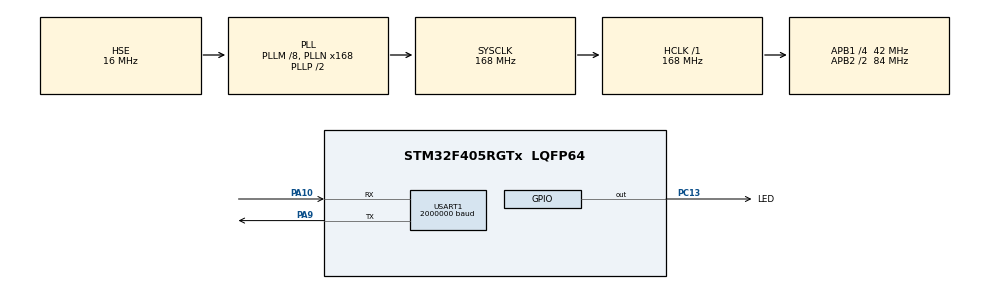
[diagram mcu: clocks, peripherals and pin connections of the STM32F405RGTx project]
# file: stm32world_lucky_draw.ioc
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Dma.Request0=USART1_RX
Dma.USART1_RX.0.Direction=DMA_PERIPH_TO_MEMORY
Dma.USART1_RX.0.FIFOMode=DMA_FIFOMODE_DISABLE
Dma.USART1_RX.0.Instance=DMA2_Stream2
Dma.USART1_RX.0.MemDataAlignment=DMA_MDATAALIGN_BYTE
Dma.USART1_RX.0.MemInc=DMA_MINC_ENABLE
Dma.USART1_RX.0.Mode=DMA_CIRCULAR
Dma.USART1_RX.0.PeriphDataAlignment=DMA_PDATAALIGN_BYTE
Dma.USART1_RX.0.PeriphInc=DMA_PINC_DISABLE
Dma.USART1_RX.0.Priority=DMA_PRIORITY_LOW
Mcu.Family=STM32F4
Mcu.Name=STM32F405RGTx
Mcu.Package=LQFP64
NVIC.DMA2_Stream2_IRQn=true\:0\:0\:false\:false\:true\:false\:true\:true
NVIC.PriorityGroup=NVIC_PRIORITYGROUP_4
NVIC.USART1_IRQn=true\:0\:0\:false\:false\:true\:true\:true\:true
PA10.Mode=Asynchronous
PA10.Signal=USART1_RX
PA13.Mode=Trace_Asynchronous_SW
PA13.Signal=SYS_JTMS-SWDIO
PA14.Mode=Trace_Asynchronous_SW
PA14.Signal=SYS_JTCK-SWCLK
PA9.Mode=Asynchronous
PA9.Signal=USART1_TX
PB3.Mode=Trace_Asynchronous_SW
PB3.Signal=SYS_JTDO-SWO
PC13-ANTI_TAMP.GPIO_Label=LED
PC13-ANTI_TAMP.GPIO_ModeDefaultOutputPP=GPIO_MODE_OUTPUT_PP
PC13-ANTI_TAMP.GPIO_PuPd=GPIO_NOPULL
PC13-ANTI_TAMP.PinState=GPIO_PIN_SET
PC13-ANTI_TAMP.Signal=GPIO_Output
PH0-OSC_IN.Mode=HSE-External-Oscillator
PH0-OSC_IN.Signal=RCC_OSC_IN
PH1-OSC_OUT.Mode=HSE-External-Oscillator
PH1-OSC_OUT.Signal=RCC_OSC_OUT
ProjectManager.HeapSize=0x200
ProjectManager.StackSize=0x400
ProjectManager.TargetToolchain=STM32CubeIDE
RCC.48MHZClocksFreq_Value=48000000
RCC.AHBFreq_Value=168000000
RCC.APB1CLKDivider=RCC_HCLK_DIV4
RCC.APB1Freq_Value=42000000
RCC.APB1TimFreq_Value=84000000
RCC.APB2CLKDivider=RCC_HCLK_DIV2
RCC.APB2Freq_Value=84000000
RCC.APB2TimFreq_Value=168000000
RCC.CortexFreq_Value=168000000
RCC.HCLKFreq_Value=168000000
RCC.HSE_VALUE=16000000
RCC.HSI_VALUE=16000000
RCC.LSE_VALUE=32768
RCC.PLLM=8
RCC.PLLN=168
RCC.PLLQ=7
RCC.PLLSourceVirtual=RCC_PLLSOURCE_HSE
RCC.SYSCLKFreq_VALUE=168000000
RCC.SYSCLKSource=RCC_SYSCLKSOURCE_PLLCLK
RCC.VCOOutputFreq_Value=336000000
USART1.BaudRate=2000000
USART1.OverSampling=UART_OVERSAMPLING_8
USART1.VirtualMode=VM_ASYNC
VP_RNG_VS_RNG.Mode=RNG_Activate
board=custom

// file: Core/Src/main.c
/* USER CODE BEGIN Header */
/**
 ******************************************************************************
 * @file           : main.c
 * @brief          : Main program body
 ******************************************************************************
 * @attention
 *
 * Copyright (c) 2024 Lars Boegild Thomsen <lth@stm32world.com>
 * All rights reserved.
 *
 * This software is licensed under terms that can be found in the LICENSE file
 * in the root directory of this software component.
 * If no LICENSE file comes with this software, it is provided AS-IS.
 *
 ******************************************************************************
 */
/* USER CODE END Header */
#include "main.h"

/* USER CODE BEGIN Includes */
#include <stdlib.h>
#include <stdio.h>
/* USER CODE END Includes */

/* USER CODE BEGIN PD */
#define PARTICIPANTS 3
#define WINNERS 3
/* USER CODE END PD */

RNG_HandleTypeDef hrng;

UART_HandleTypeDef huart1;
DMA_HandleTypeDef hdma_usart1_rx;

/* USER CODE BEGIN PV */
int8_t usart_rx_buffer[16];
uint32_t winner_list[WINNERS];
uint8_t next_winner = 0;
uint8_t list_winners = 0;
uint32_t winner_idx = 0;
/* USER CODE END PV */

void SystemClock_Config(void);
static void MX_GPIO_Init(void);
static void MX_DMA_Init(void);
static void MX_USART1_UART_Init(void);
static void MX_RNG_Init(void);

/* USER CODE BEGIN 0 */

// Send printf to uart1
int _write(int fd, char *ptr, int len) {
    HAL_StatusTypeDef hstatus;

    if (fd == 1 || fd == 2) {
        hstatus = HAL_UART_Transmit(&huart1, (uint8_t*) ptr, len, HAL_MAX_DELAY);
        if (hstatus == HAL_OK)
            return len;
        else
            return -1;
    }
    return -1;
}

void process_character(char ch) {

    switch (ch) {
    case 'l':
        list_winners = 1;
        break;
    case 'n':
        next_winner = 1;
        break;
    }

}

/**
 * @brief  UART Event Callback.  Fired on idle or if dma buffer half full or full.
 * @param  huart  Pointer to a UART_HandleTypeDef structure that contains
 *                the configuration information for the specified UART module.
 * @param  offset A offset counter pointing to last valid character in DMA buffer.
 * @retval None
 */
void HAL_UARTEx_RxEventCallback(UART_HandleTypeDef *huart, uint16_t offset) {

    static uint16_t last_offset = 0;

    // Ignore if called twice (which will happen on every half buffer)
    if (offset != last_offset) {

        // If wrap around reset last_size
        if (offset < last_offset)
            last_offset = 0;

        while (last_offset < offset) {
            process_character((char) usart_rx_buffer[last_offset]);
            ++last_offset;
        }

    }

}

/* USER CODE END 0 */

int main(void)
{

  /* MCU Configuration--------------------------------------------------------*/

  /* Reset of all peripherals, Initializes the Flash interface and the Systick. */
  HAL_Init();

  /* Configure the system clock */
  SystemClock_Config();

  /* Initialize all configured peripherals */
  MX_GPIO_Init();
  MX_DMA_Init();
  MX_USART1_UART_Init();
  MX_RNG_Init();
  /* USER CODE BEGIN 2 */

  printf("\n\n\nLucky draw start\n");

  HAL_UARTEx_ReceiveToIdle_DMA(&huart1, (uint8_t*) &usart_rx_buffer, sizeof(usart_rx_buffer));

  /* USER CODE END 2 */

  /* Infinite loop */
  /* USER CODE BEGIN WHILE */

    uint32_t now = 0, next_blink = 500;

    while (1) {

        now = uwTick;

        if (now >= next_blink) {
            HAL_GPIO_TogglePin(LED_GPIO_Port, LED_Pin);
            next_blink = now + 500;
        }

        if (next_winner) {
            if (winner_idx < sizeof(winner_list) / sizeof(winner_list[0])) {
                printf("Picking winner %lu\n", winner_idx + 1);

                while (!winner_list[winner_idx]) {

                    uint32_t new_winner = 1 + HAL_RNG_GetRandomNumber(&hrng) % WINNERS;
                    uint8_t found = 0;

                    for (int i = 0; i < winner_idx; ++i) {
                        if (winner_list[i] == new_winner) {
                            found = 1;
                        }

                        if (!found) {
                            printf("New winner: %d\n", new_winner);
                            winner_list[winner_idx] = new_winner;
                        }

                    }

                }

                ++winner_idx;

            } else {
                printf("All winners have been picked\n");
            }

            next_winner = 0;
        }

        if (list_winners) {
            //printf("List winners\n");

            printf("List of winners:\n");
            for (int i = 0; i < sizeof(winner_list) / sizeof(winner_list[0]); ++i) {
                if (winner_list[i]) printf("Winner %d: %d\n", i + 1, winner_list[i]);
            }

            list_winners = 0;
        }

    /* USER CODE END WHILE */

    }
}

void SystemClock_Config(void)
{
  RCC_OscInitTypeDef RCC_OscInitStruct = {0};
  RCC_ClkInitTypeDef RCC_ClkInitStruct = {0};

  /** Configure the main internal regulator output voltage
  */
  __HAL_RCC_PWR_CLK_ENABLE();
  __HAL_PWR_VOLTAGESCALING_CONFIG(PWR_REGULATOR_VOLTAGE_SCALE1);

  /** Initializes the RCC Oscillators according to the specified parameters
  * in the RCC_OscInitTypeDef structure.
  */
  RCC_OscInitStruct.OscillatorType = RCC_OSCILLATORTYPE_HSE;
  RCC_OscInitStruct.HSEState = RCC_HSE_ON;
  RCC_OscInitStruct.PLL.PLLState = RCC_PLL_ON;
  RCC_OscInitStruct.PLL.PLLSource = RCC_PLLSOURCE_HSE;
  RCC_OscInitStruct.PLL.PLLM = 8;
  RCC_OscInitStruct.PLL.PLLN = 168;
  RCC_OscInitStruct.PLL.PLLP = RCC_PLLP_DIV2;
  RCC_OscInitStruct.PLL.PLLQ = 7;
  if (HAL_RCC_OscConfig(&RCC_OscInitStruct) != HAL_OK)
  {
    Error_Handler();
  }

  /** Initializes the CPU, AHB and APB buses clocks
  */
  RCC_ClkInitStruct.ClockType = RCC_CLOCKTYPE_HCLK|RCC_CLOCKTYPE_SYSCLK
                              |RCC_CLOCKTYPE_PCLK1|RCC_CLOCKTYPE_PCLK2;
  RCC_ClkInitStruct.SYSCLKSource = RCC_SYSCLKSOURCE_PLLCLK;
  RCC_ClkInitStruct.AHBCLKDivider = RCC_SYSCLK_DIV1;
  RCC_ClkInitStruct.APB1CLKDivider = RCC_HCLK_DIV4;
  RCC_ClkInitStruct.APB2CLKDivider = RCC_HCLK_DIV2;

  if (HAL_RCC_ClockConfig(&RCC_ClkInitStruct, FLASH_LATENCY_5) != HAL_OK)
  {
    Error_Handler();
  }
}

static void MX_RNG_Init(void)
{

  hrng.Instance = RNG;
  if (HAL_RNG_Init(&hrng) != HAL_OK)
  {
    Error_Handler();
  }

}

static void MX_USART1_UART_Init(void)
{

  huart1.Instance = USART1;
  huart1.Init.BaudRate = 2000000;
  huart1.Init.WordLength = UART_WORDLENGTH_8B;
  huart1.Init.StopBits = UART_STOPBITS_1;
  huart1.Init.Parity = UART_PARITY_NONE;
  huart1.Init.Mode = UART_MODE_TX_RX;
  huart1.Init.HwFlowCtl = UART_HWCONTROL_NONE;
  huart1.Init.OverSampling = UART_OVERSAMPLING_8;
  if (HAL_UART_Init(&huart1) != HAL_OK)
  {
    Error_Handler();
  }

}

static void MX_DMA_Init(void)
{

  /* DMA controller clock enable */
  __HAL_RCC_DMA2_CLK_ENABLE();

  /* DMA interrupt init */
  /* DMA2_Stream2_IRQn interrupt configuration */
  HAL_NVIC_SetPriority(DMA2_Stream2_IRQn, 0, 0);
  HAL_NVIC_EnableIRQ(DMA2_Stream2_IRQn);

}

static void MX_GPIO_Init(void)
{
  GPIO_InitTypeDef GPIO_InitStruct = {0};

  /* GPIO Ports Clock Enable */
  __HAL_RCC_GPIOC_CLK_ENABLE();
  __HAL_RCC_GPIOH_CLK_ENABLE();
  __HAL_RCC_GPIOA_CLK_ENABLE();
  __HAL_RCC_GPIOB_CLK_ENABLE();

  /*Configure GPIO pin Output Level */
  HAL_GPIO_WritePin(LED_GPIO_Port, LED_Pin, GPIO_PIN_SET);

  /*Configure GPIO pin : LED_Pin */
  GPIO_InitStruct.Pin = LED_Pin;
  GPIO_InitStruct.Mode = GPIO_MODE_OUTPUT_PP;
  GPIO_InitStruct.Pull = GPIO_NOPULL;
  GPIO_InitStruct.Speed = GPIO_SPEED_FREQ_LOW;
  HAL_GPIO_Init(LED_GPIO_Port, &GPIO_InitStruct);

}

void Error_Handler(void)
{
    __disable_irq();
    while (1)
    {
    }
}
